# adc_reva_me10 register map
Registers are 32-bit, read-write, no defined reset value unless marked. A register's access mark holds for its fields unless they carry their own. Offsets are from the block's base; lines under a group give offsets from that group; [hi:lo] are bit positions; {n}, {i} and the like mark numbered series; 'fields as' and 'values as' point back to an identical list; <NAME> marks a mode.

## Memory map
0x40034000 ADC size 0x1000 — 10-bit Analog to Digital Converter

## Interrupts
20 ADC — ADC IRQ

## ADC — 10-bit Analog to Digital Converter
Base 0x40034000
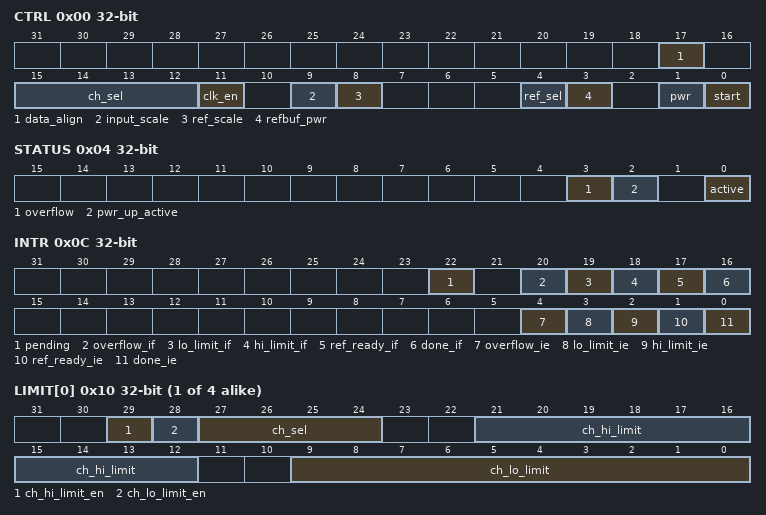
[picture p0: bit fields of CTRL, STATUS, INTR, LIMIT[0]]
0x00 CTRL — ADC Control
  [17] data_align — ADC Data Alignment Select
    0=lsb_justified; 1=msb_justified
  [15:12] ch_sel — ADC Channel Select
    {v}=ain{v} (v=0..3); 4=ain0_div5; 5=ain1_div5; 6=vddb_div4; 7=vdda; 8=vcore; 9=vrtc_div2; 10=rsv_0xa; 11=vddio_div4; 12=vddioh_div4
  [11] clk_en — ADC Clock Enable
    0=dis; 1=en
  [9] input_scale — ADC Scale
    0=div1; 1=div2
  [8] ref_scale — ADC Reference Scale
    0=div1; 1=div2
  [4] ref_sel — ADC Reference Select
    0=bandgap; 1=vdd_div2
  [3] refbuf_pwr — ADC Reference Buffer Power Up
    0=refbuf_off; 1=refbuf_on
  [1] pwr — ADC Power Up
    0=adc_off; 1=adc_on
  [0] start — Start ADC Conversion
    0=inactive; 1=start
0x04 STATUS — ADC Status
  [3] overflow ro — ADC Overflow
    0=underflow; 1=overflow
  [2] pwr_up_active ro — AFE Power Up Delay Active
    0=no_delay; 1=delay_active
  [0] active ro — ADC Conversion In Progress
    0=idle; 1=active
0x08 DATA — ADC Output Data
  [15:0] data ro — ADC Converted Sample Data Output
0x0C INTR — ADC Interrupt Control Register
  [22] pending ro — ADC Interrupt Pending Status
    0=no_int; 1=int_pending
  [20] overflow_if write-1-clears — ADC Overflow Interrupt Flag
    0=inactive; 1=active
  [19] lo_limit_if write-1-clears — ADC Lo Limit Monitor Interrupt Flag
    0=inactive; 1=active
  [18] hi_limit_if write-1-clears — ADC Hi Limit Monitor Interrupt Flag
    0=inactive; 1=active
  [17] ref_ready_if write-1-clears — ADC Reference Ready Interrupt Flag
    0=inactive; 1=active
  [16] done_if write-1-clears — ADC Done Interrupt Flag
    0=inactive; 1=active
  [4] overflow_ie — ADC Overflow Interrupt Enable
    0=dis; 1=en
  [3] lo_limit_ie — ADC Lo Limit Monitor Interrupt Enable
    0=dis; 1=en
  [2] hi_limit_ie — ADC Hi Limit Monitor Interrupt Enable
    0=dis; 1=en
  [1] ref_ready_ie — ADC Reference Ready Interrupt Enable
    0=dis; 1=en
  [0] done_ie — ADC Done Interrupt Enable
    0=dis; 1=en
{0x10+4i} LIMIT[{i}] (i=0..3) — ADC Limit
  [29] ch_hi_limit_en — High Limit Monitoring Enable
    0=dis; 1=en
  [28] ch_lo_limit_en — Low Limit Monitoring Enable
    0=dis; 1=en
  [27:24] ch_sel — ADC Channel Select
    {v}=ain{v} (v=0..12)
  [21:12] ch_hi_limit — High Limit Threshold
  [9:0] ch_lo_limit — Low Limit Threshold
